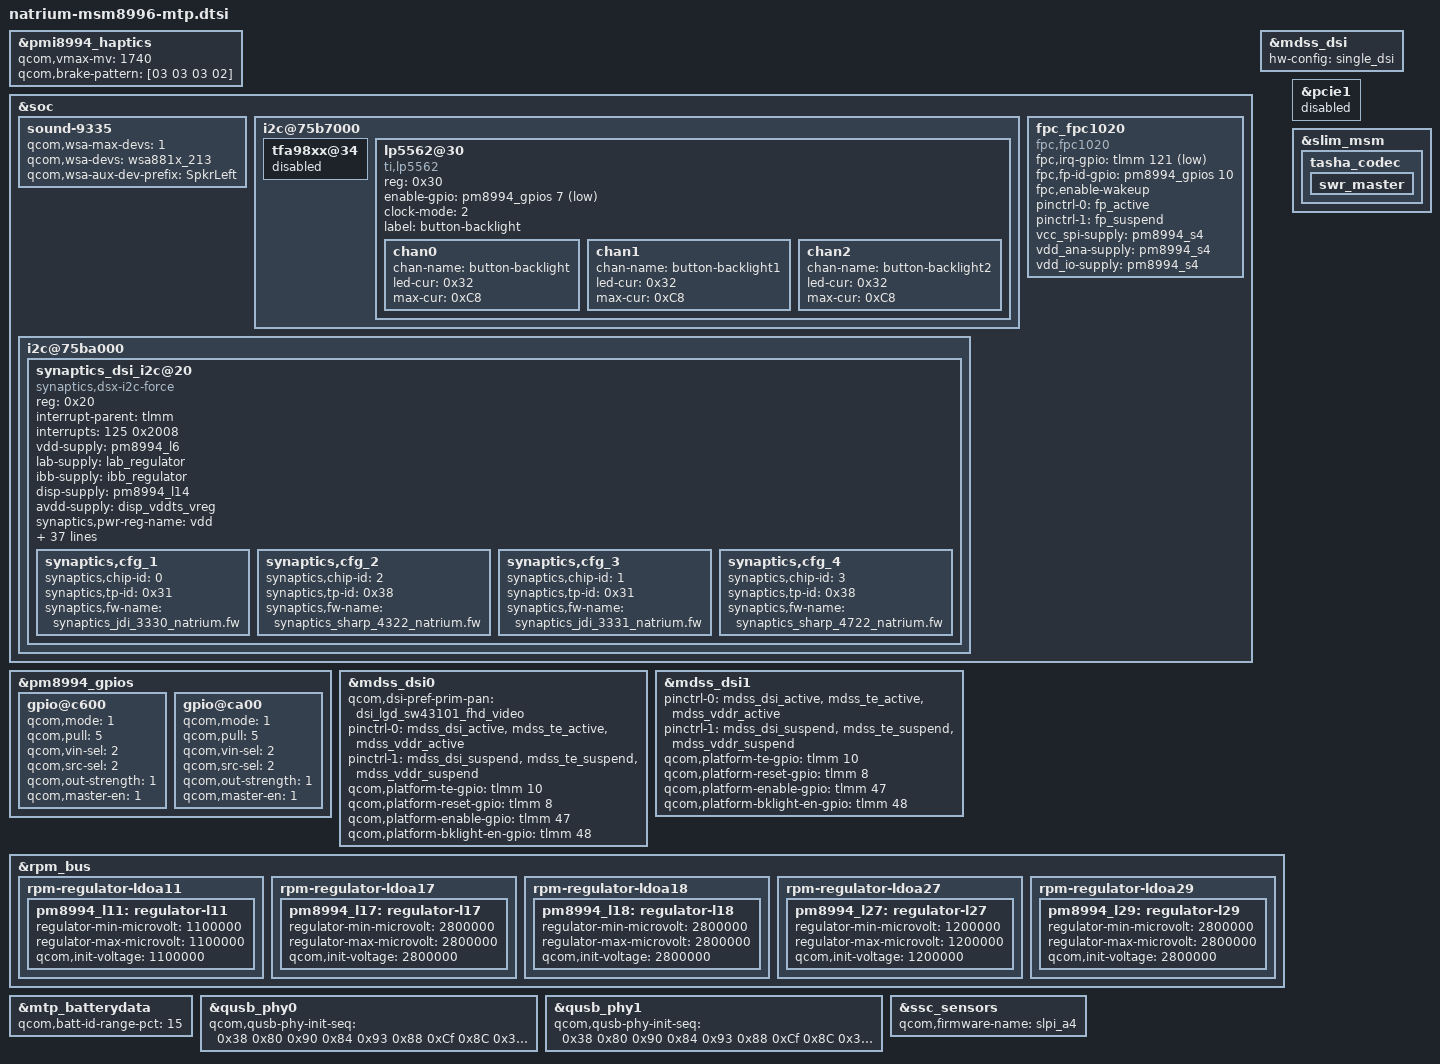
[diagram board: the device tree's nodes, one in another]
/* Copyright (c) 2015, The Linux Foundation. All rights reserved.
 * Copyright (C) 2016 XiaoMi, Inc.
 *
 * This program is free software; you can redistribute it and/or modify
 * it under the terms of the GNU General Public License version 2 and
 * only version 2 as published by the Free Software Foundation.
 *
 * This program is distributed in the hope that it will be useful,
 * but WITHOUT ANY WARRANTY; without even the implied warranty of
 * MERCHANTABILITY or FITNESS FOR A PARTICULAR PURPOSE.  See the
 * GNU General Public License for more details.
 */

#include "msm8996-xiaomi-common.dtsi"
#include "msm8996-camera-sensor-natrium.dtsi"
#include "msm8996-wsa881x.dtsi"

&pmi8994_haptics {
	status = "ok";
	qcom,vmax-mv = <1740>;
	qcom,brake-pattern = [03 03 03 02];
};

&soc {
	sound-9335 {
		qcom,wsa-max-devs = <1>;
		qcom,wsa-devs = <&wsa881x_213>;
		qcom,wsa-aux-dev-prefix = "SpkrLeft";
	};

	i2c@75b7000 {
		tfa98xx@34 {
			status = "disabled";
		};
		lp5562@30 {
			compatible = "ti,lp5562";
			reg = <0x30>;
			enable-gpio = <&pm8994_gpios 7 1>;
			clock-mode = /bits/8 <2>;
			label = "button-backlight";
			chan0 {
				chan-name = "button-backlight";
				led-cur = /bits/ 8 <0x32>;
				max-cur = /bits/ 8 <0xC8>;
			};

			chan1 {
				chan-name = "button-backlight1";
				led-cur = /bits/ 8 <0x32>;
				max-cur = /bits/ 8 <0xC8>;
			};

			chan2 {
				chan-name = "button-backlight2";
				led-cur = /bits/ 8 <0x32>;
				max-cur = /bits/ 8 <0xC8>;
			};
		};
	};

	i2c@75ba000 {
		synaptics_dsi_i2c@20 {
			compatible = "synaptics,dsx-i2c-force";
			reg = <0x20>;
			interrupt-parent = <&tlmm>;
			interrupts = <125 0x2008>;
			vdd-supply = <&pm8994_l6>;
			lab-supply = <&lab_regulator>;
			ibb-supply = <&ibb_regulator>;
			disp-supply = <&pm8994_l14>;
			avdd-supply = <&disp_vddts_vreg>;
			synaptics,pwr-reg-name = "vdd";
			synaptics,lab-reg-name = "lab";
			synaptics,ibb-reg-name = "ibb";
			synaptics,disp-reg-name = "disp";
			synaptics,bus-reg-name = "avdd";
			synaptics,ub-i2c-addr = <0x2c>;
			pinctrl-names = "pmx_ts_active", "pmx_ts_suspend";
			pinctrl-0 = <&ts_active>;
			pinctrl-1 = <&ts_suspend>;
			synaptics,mdss-dsi-reset = <&tlmm 8 0>;
			synaptics,reset-gpio = <&tlmm 89 0x00>;
			synaptics,irq-gpio = <&tlmm 125 0x2008>;
			synaptics,reset-gpio-name = "dsx_reset";
			synaptics,irq-gpio-name = "dsx_irq";
			synaptics,irq-on-state = <0>;
			synaptics,irq-flags = <0x2008>; /* IRQF_ONESHOT | IRQF_TRIGGER_LOW */
			synaptics,power-delay-ms = <5>;
			synaptics,reset-delay-ms = <200>;
			synaptics,reset-active-ms = <5>;
			synaptics,power-on-state = <1>;
			synaptics,reset-on-state = <0>;
			synaptics,mdss-reset-state = <1>;
			synaptics,cap-button-codes = <158 139 102>;
			synaptics,power-ctrl;
			synaptics,short-jdi-25 = "000: 0xff\n001: 0xff\n002: 0xef\n003: 0xff\n004: 0x03\n005: 0x00\n006: 0x00";
			synaptics,short-jdi-26 = "000: 0x03\n001: 0x00\n002: 0x00\n003: 0x00\n004: 0x03\n005: 0x00\n006: 0x00";
			clock-names = "iface_clk", "core_clk";
			clocks = <&clock_gcc clk_gcc_blsp2_ahb_clk>,
				<&clock_gcc clk_gcc_blsp2_qup6_i2c_apps_clk>;
			synaptics,backup-fw = "synaptics_sharp_backup_natrium.fw";
			synaptics,chip-3330 = <0>;
			synaptics,chip-3331 = <1>;
			synaptics,chip-4322 = <2>;
			synaptics,chip-4722 = <3>;
			synaptics,guest-serialization-as-lockdown;
			synaptics,tp-id-byte = /bits/ 8 <0>;
			synaptics,config-array-size = <4>;
			synaptics,cfg_1 {
				synaptics,chip-id = <0>;
				synaptics,tp-id = /bits/ 8 <0x31>;
				synaptics,fw-name = "synaptics_jdi_3330_natrium.fw";
			};
			synaptics,cfg_2 {
				synaptics,chip-id = <2>;
				synaptics,tp-id = /bits/ 8 <0x38>;
				synaptics,fw-name = "synaptics_sharp_4322_natrium.fw";
			};
			synaptics,cfg_3 {
				synaptics,chip-id = <1>;
				synaptics,tp-id = /bits/ 8 <0x31>;
				synaptics,fw-name = "synaptics_jdi_3331_natrium.fw";
			};
			synaptics,cfg_4 {
				synaptics,chip-id = <3>;
				synaptics,tp-id = /bits/ 8 <0x38>;
				synaptics,fw-name = "synaptics_sharp_4722_natrium.fw";
			};

		};
	};

	fpc_fpc1020 {
		compatible = "fpc,fpc1020";
		fpc,irq-gpio	= <&tlmm 121 0x2001>;
		fpc,fp-id-gpio = <&pm8994_gpios 10 0x00>;
		fpc,enable-wakeup;
		pinctrl-names = "pmx_fp_active", "pmx_fp_suspend";
		pinctrl-0 = <&fp_active>;
		pinctrl-1 = <&fp_suspend>;
		vcc_spi-supply	= <&pm8994_s4>;
		vdd_ana-supply	= <&pm8994_s4>;
		vdd_io-supply	= <&pm8994_s4>;
	};
};

&pm8994_gpios {
	gpio@c600 {
		qcom,mode = <1>;		/* Digital out */ qcom,pull = <5>;		/* NO PULL */
		qcom,vin-sel = <2>;		/* Logical 1 voltage value 1.8v */
		qcom,src-sel = <2>;		/* QPNP_PIN_SEL_FUNC_CONSTANT */
		qcom,pull = <5>;		/* NO PULL */
		qcom,out-strength = <1>;/* Low drive strength */
		qcom,master-en = <1>;
		status = "okay";
	};

	gpio@ca00 {
		qcom,mode = <1>;		/* Digital out */ qcom,pull = <5>;		/* NO PULL */
		qcom,vin-sel = <2>;		/* Logical 1 voltage value 1.8v */
		qcom,src-sel = <2>;		/* QPNP_PIN_SEL_FUNC_CONSTANT */
		qcom,pull = <5>;		/* NO PULL */
		qcom,out-strength = <1>;/* Low drive strength */
		qcom,master-en = <1>;
		status = "okay";
	};
};

&mdss_dsi {
	hw-config = "single_dsi";
};
&mdss_dsi0 {
	qcom,dsi-pref-prim-pan = <&dsi_lgd_sw43101_fhd_video>;
	pinctrl-names = "mdss_default", "mdss_sleep";
	pinctrl-0 = <&mdss_dsi_active &mdss_te_active &mdss_vddr_active>;
	pinctrl-1 = <&mdss_dsi_suspend &mdss_te_suspend &mdss_vddr_suspend>;
	qcom,platform-te-gpio = <&tlmm 10 0>;
	qcom,platform-reset-gpio = <&tlmm 8 0>;
	qcom,platform-enable-gpio = <&tlmm 47 0>;
	qcom,platform-bklight-en-gpio = <&tlmm 48 0>;
};

&mdss_dsi1 {
	pinctrl-names = "mdss_default", "mdss_sleep";
	pinctrl-0 = <&mdss_dsi_active &mdss_te_active &mdss_vddr_active>;
	pinctrl-1 = <&mdss_dsi_suspend &mdss_te_suspend &mdss_vddr_suspend>;
	qcom,platform-te-gpio = <&tlmm 10 0>;
	qcom,platform-reset-gpio = <&tlmm 8 0>;
	qcom,platform-enable-gpio = <&tlmm 47 0>;
	qcom,platform-bklight-en-gpio = <&tlmm 48 0>;
};

&rpm_bus {
	rpm-regulator-ldoa11 {
		status = "okay";
		pm8994_l11: regulator-l11 {
			regulator-min-microvolt = <1100000>;
			regulator-max-microvolt = <1100000>;
			qcom,init-voltage = <1100000>;
			status = "okay";
		};
	};

	rpm-regulator-ldoa17 {
		status = "okay";
		pm8994_l17: regulator-l17 {
			regulator-min-microvolt = <2800000>;
			regulator-max-microvolt = <2800000>;
			qcom,init-voltage = <2800000>;
			status = "okay";
		};
	};

	rpm-regulator-ldoa18 {
		status = "okay";
		pm8994_l18: regulator-l18 {
			regulator-min-microvolt = <2800000>;
			regulator-max-microvolt = <2800000>;
			qcom,init-voltage = <2800000>;
			status = "okay";
		};
	};

	rpm-regulator-ldoa27 {
		status = "okay";
		pm8994_l27: regulator-l27 {
			regulator-min-microvolt = <1200000>;
			regulator-max-microvolt = <1200000>;
			qcom,init-voltage = <1200000>;
			status = "okay";
		};
	};

	rpm-regulator-ldoa29 {
		status = "okay";
		pm8994_l29: regulator-l29 {
			regulator-min-microvolt = <2800000>;
			regulator-max-microvolt = <2800000>;
			qcom,init-voltage = <2800000>;
			status = "okay";
		};
	};
};

&mtp_batterydata {
	qcom,batt-id-range-pct = <15>;
	#include "batterydata-natrium-atl-3800mah.dtsi"
	#include "batterydata-natrium-lg-3800mah.dtsi"
	#include "batterydata-itech-3020mah.dtsi"
};

&qusb_phy0 {
	qcom,qusb-phy-init-seq = <0x38 0x80
			0x90 0x84
			0x93 0x88
			0xCf 0x8C
			0x30 0x08
			0x79 0x0C
			0x21 0x10
			0x14 0x9C
			0x9F 0x1C
			0x00 0x18>;
};

&qusb_phy1 {
	qcom,qusb-phy-init-seq = <0x38 0x80
			0x90 0x84
			0x93 0x88
			0xCf 0x8C
			0x30 0x08
			0x79 0x0C
			0x21 0x10
			0x14 0x9C
			0x9F 0x1C
			0x00 0x18>;
};

&ssc_sensors {
	qcom,firmware-name = "slpi_a4";
};

&pcie1 {
	status = "disabled";
};

// msm8996-wsa881x.dtsi start
&slim_msm {
	tasha_codec {
		swr_master {
			/delete-node/ wsa881x@20170211;
			/delete-node/ wsa881x@20170212;
			/delete-node/ wsa881x@21170214;
		};
	};
};
// msm8996-wsa881x.dtsi end
